AUTOSAR XML (schema 4-0-3)
package /ComponentTypes
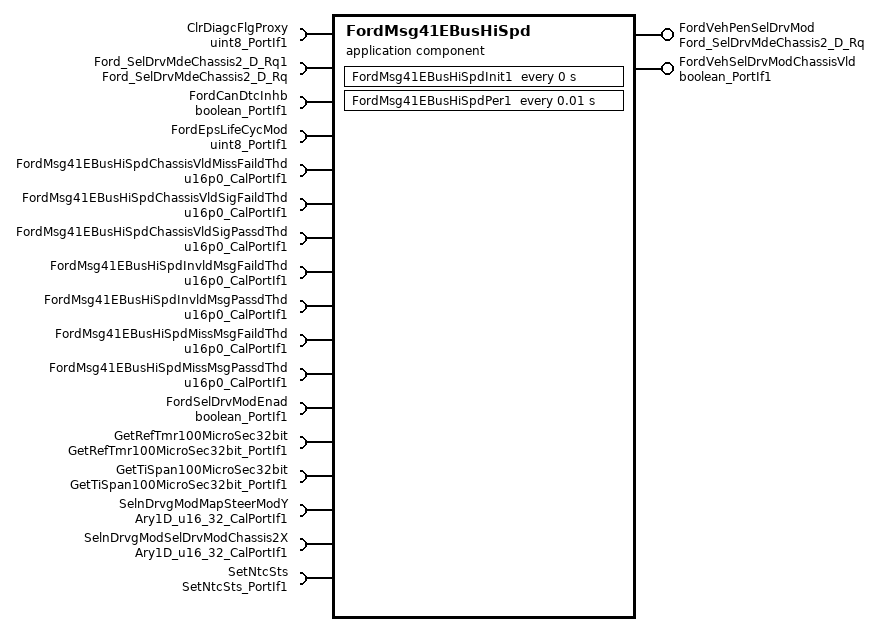
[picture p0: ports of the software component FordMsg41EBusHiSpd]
  application sw component type FordMsg41EBusHiSpd  # The purpose of the Ford Message 41E Bus High Speed function is to provide the Electric Power Steering system with signal values for the Select Drive Mode function from CAN. The Ford Message 41E function will perform the missing message and signal invalid diagnostics as well as provide a validity flag for the signal values and received message.
    provide port FordVehPenSelDrvMod: nonqueued-sender-com-spec{data-element=Ford_SelDrvMdeChassis2_D_Rq, init-value=0}, provided-interface=Ford_SelDrvMdeChassis2_D_Rq  # Processed Personalization Select Drive Mode to be used by EPS
    provide port FordVehSelDrvModChassisVld: nonqueued-sender-com-spec{data-element=Logl, init-value=0}, provided-interface=boolean_PortIf1  # This signal Check the validity of Ford Vehicle Select Drive Mode Chassis signal
    17 x require port:
      ClrDiagcFlgProxy: nonqueued-receiver-com-spec{data-element=Val, filter=data-filter-type=ALWAYS, init-value=0}, required-interface=uint8_PortIf1  # When ClrDiagcFlgProxy is True, Diagnostic test is performed
      Ford_SelDrvMdeChassis2_D_Rq1: nonqueued-receiver-com-spec{data-element=Ford_SelDrvMdeChassis2_D_Rq, filter=data-filter-type=ALWAYS, init-value=0}, required-interface=Ford_SelDrvMdeChassis2_D_Rq  # Ford Personalization Select Drive Mode
      FordCanDtcInhb: nonqueued-receiver-com-spec{data-element=Logl, filter=data-filter-type=ALWAYS, init-value=1}, required-interface=boolean_PortIf1
      FordEpsLifeCycMod: nonqueued-receiver-com-spec{data-element=Val, filter=data-filter-type=ALWAYS, init-value=0}, required-interface=uint8_PortIf1  # This signal is used to decide calibration value to FAIL the NTC
      FordMsg41EBusHiSpdChassisVldMissFaildThd: parameter-require-com-spec{init-value=5000, parameter=Val}, required-interface=u16p0_CalPortIf1  # Threshold to set the output Ford Vehicle Select Drive Mode Chassis Valid to False
      FordMsg41EBusHiSpdChassisVldSigFaildThd: parameter-require-com-spec{init-value=0, parameter=Val}, required-interface=u16p0_CalPortIf1  # Threshold to set the output Ford Vehicle Select Drive Mode Chassis Valid to False
      FordMsg41EBusHiSpdChassisVldSigPassdThd: parameter-require-com-spec{init-value=0, parameter=Val}, required-interface=u16p0_CalPortIf1  # Threshold to set the output Ford Vehicle Select Drive Mode Chassis Valid to True
      FordMsg41EBusHiSpdInvldMsgFaildThd: parameter-require-com-spec{init-value=0, parameter=Val}, required-interface=u16p0_CalPortIf1  # Threshold to set the Invalid message NTC
      FordMsg41EBusHiSpdInvldMsgPassdThd: parameter-require-com-spec{init-value=0, parameter=Val}, required-interface=u16p0_CalPortIf1  # Threshold to clear the Invalid message NTC
      FordMsg41EBusHiSpdMissMsgFaildThd: parameter-require-com-spec{init-value=5000, parameter=Val}, required-interface=u16p0_CalPortIf1  # Threshold to set the Missing message NTC
      FordMsg41EBusHiSpdMissMsgPassdThd: parameter-require-com-spec{init-value=0, parameter=Val}, required-interface=u16p0_CalPortIf1  # Threshold to clear the Missing message NTC
      FordSelDrvModEnad: nonqueued-receiver-com-spec{data-element=Logl, filter=data-filter-type=ALWAYS, init-value=0}, required-interface=boolean_PortIf1  # This signal should be set to 1 in order to Test Diagnostic NTC
      GetRefTmr100MicroSec32bit: client-com-spec=Oper, required-interface=GetRefTmr100MicroSec32bit_PortIf1  # It captures simulation time fromthe SimnTi value obtained at root layer of model and gives the RefTmr
      GetTiSpan100MicroSec32bit: client-com-spec=Oper, required-interface=GetTiSpan100MicroSec32bit_PortIf1  # It captures simulation time fromSimnTi value, handles counter wrapping and subtracts RefTmr, provides the TiSpan
      SelnDrvgModMapSteerModY: parameter-require-com-spec{init-value=[0, 1, 2, 3, 4, 5, 6, 7, 8, 9, 10, 11, 12, 13, 14, 15, 16, 17, 18, 19, 20, 21, 22, 23, 24, 25, 26, 27, 28, 29, 30, 31], parameter=Ary1D}, required-interface=Ary1D_u16_32_CalPortIf1
      SelnDrvgModSelDrvModChassis2X: parameter-require-com-spec{init-value=[0, 1, 2, 3, 4, 5, 6, 7, 8, 9, 10, 11, 12, 13, 14, 15, 16, 17, 18, 19, 20, 21, 22, 23, 24, 25, 26, 27, 28, 29, 30, 31], parameter=Ary1D}, required-interface=Ary1D_u16_32_CalPortIf1
      SetNtcSts: client-com-spec=Oper, required-interface=SetNtcSts_PortIf1  # Returns the NTC Qualifier status
    behavior FordMsg41EBusHiSpd_InternalBehavior
      ar-typed-per-instance-memorys:
        12 x data, all with sw-calibration-access=READ-ONLY:
          ClrDiagcFlgProxyPrev: type=uint8  # Clear Diagc Flag Proxy
          FirstTranVldFlg: type=boolean  # This flag is used to indicate the reception of first message
          FordVehMsg41EMiss: type=boolean  # Previous value of Ford Vehicle Propulsion Wheel Torque Valid
          FordVehPenSelDrvModPrev: type=Ford_SelDrvMdeChassis2_D_Rq  # Hold the Previous value of Ford Vehicle Personalization Select Drive Mode
          FordVehSelDrvModChassisVldFaildRefTi: type=uint32  # Timer for Select Drive Mode Chassis Valid Failed Reference Time will increment or reset based on the conditions
          FordVehSelDrvModChassisVldMissRefTi: type=uint32  # Timer for Ford Vehicle Select Drive Mode Chassis Valid Missing Reference Time will incrementor reset based on the conditions
          FordVehSelDrvModChassisVldPassdRefTi: type=uint32  # Timer for Ford Vehicle Select Drive Mode Chassis Valid Passed Reference Time will increment or reset based on the conditions
          FordVehSelDrvModChassisVldPrev: type=boolean  # Previous Value of Ford Vehicle Select Drive Mode Chassis Valid
          InvldMsgFaildRefTi: type=uint32  # Timer for invalid message will increment or reset based on the conditions
          InvldMsgPassdRefTi: type=uint32  # Timer for invalid message will increment or reset based on the conditions
          MissMsgFaildRefTi: type=uint32  # Timer for missing message will increment or reset based on the conditions
          MissMsgPassdRefTi: type=uint32  # Timer for missing message will increment or reset based on the conditions
      timing event FordMsg41EBusHiSpd_InitEvent: start-on-event=FordMsg41EBusHiSpdInit1, period=0
      timing event TMT_FordMsg41EBusHiSpdPer1: start-on-event=FordMsg41EBusHiSpdPer1, period=0.01
      port-api-options:
        enable-take-address=false, indirect-api=false, port=ClrDiagcFlgProxy
        enable-take-address=false, indirect-api=false, port=Ford_SelDrvMdeChassis2_D_Rq1
        enable-take-address=false, indirect-api=false, port=FordCanDtcInhb
        enable-take-address=false, indirect-api=false, port=FordEpsLifeCycMod
        enable-take-address=false, indirect-api=false, port=FordMsg41EBusHiSpdChassisVldMissFaildThd
        enable-take-address=false, indirect-api=false, port=FordMsg41EBusHiSpdChassisVldSigFaildThd
        enable-take-address=false, indirect-api=false, port=FordMsg41EBusHiSpdChassisVldSigPassdThd
        enable-take-address=false, indirect-api=false, port=FordMsg41EBusHiSpdInvldMsgFaildThd
        enable-take-address=false, indirect-api=false, port=FordMsg41EBusHiSpdInvldMsgPassdThd
        enable-take-address=false, indirect-api=false, port=FordMsg41EBusHiSpdMissMsgPassdThd
        enable-take-address=false, indirect-api=false, port=FordSelDrvModEnad
        enable-take-address=false, indirect-api=false, port=FordVehPenSelDrvMod
        enable-take-address=false, indirect-api=false, port=GetTiSpan100MicroSec32bit
        enable-take-address=false, indirect-api=false, port=SelnDrvgModMapSteerModY
        enable-take-address=false, indirect-api=false, port=SelnDrvgModSelDrvModChassis2X
        enable-take-address=false, indirect-api=false, port=SetNtcSts
      runnable FordMsg41EBusHiSpdInit1  # Initialization Runnable
        sync call SC_GetRefTmr100MicroSec32bit_Oper: operation=GetRefTmr100MicroSec32bit.Oper, timeout=0
      runnable FordMsg41EBusHiSpdPer1  # Periodic Runnable at 10 milli-seconds
        data-receive-point-by-arguments:
          5 x access:
            REC_ClrDiagcFlgProxy_Val: accessed-variable=ClrDiagcFlgProxy.Val
            REC_Ford_SelDrvMdeChassis2_D_Rq1_Ford_SelDrvMdeChassis2_D_Rq: accessed-variable=Ford_SelDrvMdeChassis2_D_Rq1.Ford_SelDrvMdeChassis2_D_Rq
            REC_FordCanDtcInhb_Logl: accessed-variable=FordCanDtcInhb.Logl
            REC_FordEpsLifeCycMod_Val: accessed-variable=FordEpsLifeCycMod.Val
            REC_FordSelDrvModEnad_Logl: accessed-variable=FordSelDrvModEnad.Logl
        data-send-points:
          access SEND_FordVehPenSelDrvMod_Ford_SelDrvMdeChassis2_D_Rq: accessed-variable=FordVehPenSelDrvMod.Ford_SelDrvMdeChassis2_D_Rq
          access SEND_FordVehSelDrvModChassisVld_Logl: accessed-variable=FordVehSelDrvModChassisVld.Logl
        sync call SC_GetRefTmr100MicroSec32bit_Oper: operation=GetRefTmr100MicroSec32bit.Oper, timeout=0
        sync call SC_GetTiSpan100MicroSec32bit_Oper: operation=GetTiSpan100MicroSec32bit.Oper, timeout=0
        sync call SC_SetNtcSts_Oper: operation=SetNtcSts.Oper, timeout=0
  swc implementation FordMsg41EBusHiSpd_Implementation: behavior=FordMsg41EBusHiSpd_InternalBehavior
    code-descriptors:
      code Default: artifact-descriptors=autosar-engineering-object={short-label=Default, category=SWSRC}
